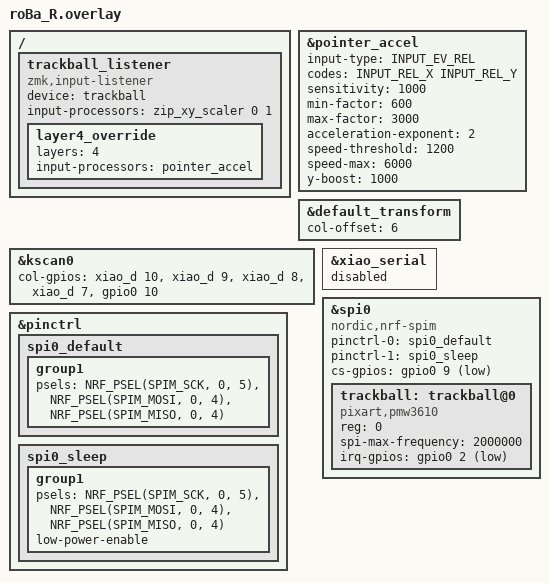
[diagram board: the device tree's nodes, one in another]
#include "roBa.dtsi"
#include <input/processors.dtsi>

/* 加速度プロセッサのパラメータ設定（PMW3610向けの標準的な目安値） */
&pointer_accel {
    input-type = <INPUT_EV_REL>;
    codes = <INPUT_REL_X INPUT_REL_Y>;
    sensitivity = <1000>;        /* 全体感度（1000が等倍） */
    min-factor = <600>;          /* ゆっくり動かした時の最小倍率（0.6倍） */
    max-factor = <3000>;         /* 素早く動かした時の最大倍率（3.0倍） */
    acceleration-exponent = <2>; /* 加速カーブ（1: 線形, 2: 二次曲線） */
    speed-threshold = <1200>;    /* 加速が始まる速度のしきい値 */
    speed-max = <6000>;          /* 最大倍率に達する速度の上限 */
    y-boost = <1000>;            /* Y軸（上下）の追加補正（1000が等倍） */
};

&default_transform {
    col-offset = <6>;
};

&kscan0 {
        col-gpios
            = <&xiao_d 10 GPIO_ACTIVE_HIGH>
            , <&xiao_d 9 GPIO_ACTIVE_HIGH>
            , <&xiao_d 8 GPIO_ACTIVE_HIGH>
            , <&xiao_d 7 GPIO_ACTIVE_HIGH>
            , <&gpio0 10 GPIO_ACTIVE_HIGH>
            ;
};

/ {
    trackball_listener {
        status = "okay";
        compatible = "zmk,input-listener";
        device = <&trackball>;

        /* ベース（デフォルト）設定：移動速度を0倍にしてトラックボールを無効化 */
        input-processors = <&zip_xy_scaler 0 1>;

        /* レイヤー4の時だけ上書きする設定 */
        layer4_override {
            layers = <4>;
            /* 加速度設定を適用 */
            input-processors = <&pointer_accel>;
        };
    };
};

&pinctrl {
    spi0_default: spi0_default {
        group1 {
            psels = <NRF_PSEL(SPIM_SCK, 0, 5)>,
                <NRF_PSEL(SPIM_MOSI, 0, 4)>,
                <NRF_PSEL(SPIM_MISO, 0, 4)>;
        };
    };

    spi0_sleep: spi0_sleep {
        group1 {
            psels = <NRF_PSEL(SPIM_SCK, 0, 5)>,
                <NRF_PSEL(SPIM_MOSI, 0, 4)>,
                <NRF_PSEL(SPIM_MISO, 0, 4)>;
            low-power-enable;
        };
    };
};

&xiao_serial { status = "disabled"; };

&spi0 {
    status = "okay";
    compatible = "nordic,nrf-spim";
    pinctrl-0 = <&spi0_default>;
    pinctrl-1 = <&spi0_sleep>;
    pinctrl-names = "default", "sleep";
    cs-gpios = <&gpio0 9 GPIO_ACTIVE_LOW>;

    trackball: trackball@0 {
        status = "okay";
        compatible = "pixart,pmw3610";
        reg = <0>;
        spi-max-frequency = <2000000>;
        irq-gpios = <&gpio0 2 (GPIO_ACTIVE_LOW | GPIO_PULL_UP)>;
    };
};
